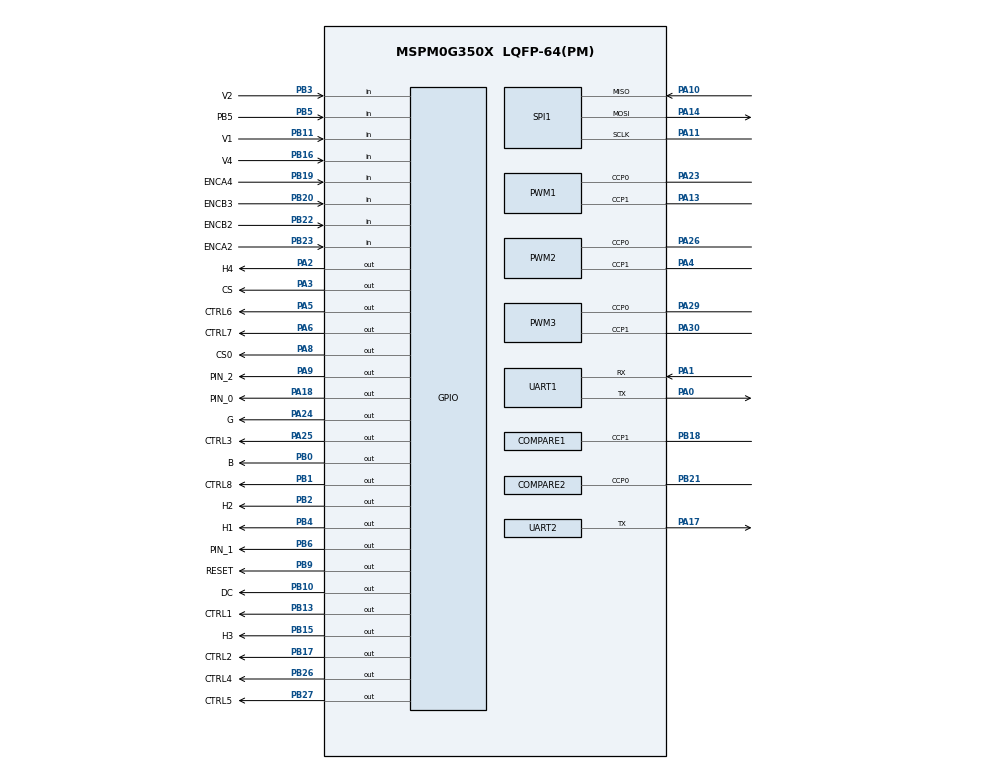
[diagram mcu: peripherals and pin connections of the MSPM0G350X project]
/**
 * @cliArgs --device "MSPM0G350X" --part "Default" --package "LQFP-64(PM)" --product "mspm0_sdk@2.05.01.01"
 * @versions {"tool":"1.23.0+4000"}
 */

/**
 * Import the modules used in this configuration.
 */
const ADC12         = scripting.addModule("/ti/driverlib/ADC12", {}, false);
const ADC121        = ADC12.addInstance();
const ADC122        = ADC12.addInstance();
const COMPARE       = scripting.addModule("/ti/driverlib/COMPARE", {}, false);
const COMPARE1      = COMPARE.addInstance();
const COMPARE2      = COMPARE.addInstance();
const GPIO          = scripting.addModule("/ti/driverlib/GPIO", {}, false);
const GPIO1         = GPIO.addInstance();
const GPIO2         = GPIO.addInstance();
const GPIO3         = GPIO.addInstance();
const GPIO4         = GPIO.addInstance();
const GPIO5         = GPIO.addInstance();
const GPIO6         = GPIO.addInstance();
const GPIO7         = GPIO.addInstance();
const GPIO8         = GPIO.addInstance();
const GPIO9         = GPIO.addInstance();
const GPIO10        = GPIO.addInstance();
const I2C           = scripting.addModule("/ti/driverlib/I2C", {}, false);
const I2C1          = I2C.addInstance();
const NONMAIN       = scripting.addModule("/ti/driverlib/NONMAIN");
const PWM           = scripting.addModule("/ti/driverlib/PWM", {}, false);
const PWM1          = PWM.addInstance();
const PWM2          = PWM.addInstance();
const PWM3          = PWM.addInstance();
const SPI           = scripting.addModule("/ti/driverlib/SPI", {}, false);
const SPI1          = SPI.addInstance();
const SYSCTL        = scripting.addModule("/ti/driverlib/SYSCTL");
const TIMER         = scripting.addModule("/ti/driverlib/TIMER", {}, false);
const TIMER1        = TIMER.addInstance();
const UART          = scripting.addModule("/ti/driverlib/UART", {}, false);
const UART1         = UART.addInstance();
const UART2         = UART.addInstance();
const UART3         = UART.addInstance();
const ProjectConfig = scripting.addModule("/ti/project_config/ProjectConfig");

/**
 * Write custom configuration values to the imported modules.
 */
ADC121.$name                             = "VCC_ADC";
ADC121.sampClkDiv                        = "DL_ADC12_CLOCK_DIVIDE_8";
ADC121.repeatMode                        = true;
ADC121.sampleTime0                       = "100 us";
ADC121.enabledInterrupts                 = ["DL_ADC12_INTERRUPT_MEM0_RESULT_LOADED"];
ADC121.samplingOperationMode             = "sequence";
ADC121.peripheral.adcPin0.$assign        = "PA15";
ADC121.adcPin0Config.hideOutputInversion = scripting.forceWrite(false);
ADC121.adcPin0Config.$name               = "ti_driverlib_gpio_GPIOPinGeneric9";

ADC122.$name                             = "ADC1";
ADC122.sampClkDiv                        = "DL_ADC12_CLOCK_DIVIDE_8";
ADC122.sampleTime0                       = "1ms";
ADC122.adcMem0_name                      = "ADC_Channel0";
ADC122.peripheral.$assign                = "ADC0";
ADC122.peripheral.adcPin0.$assign        = "PA27";
ADC122.adcPin0Config.hideOutputInversion = scripting.forceWrite(false);
ADC122.adcPin0Config.$name               = "ti_driverlib_gpio_GPIOPinGeneric16";

const Board = scripting.addModule("/ti/driverlib/Board", {}, false);

COMPARE1.ccIndex                            = 1;
COMPARE1.timerClkPrescale                   = 2;
COMPARE1.timerPeriod                        = 1;
COMPARE1.interrupts                         = ["LOAD"];
COMPARE1.$name                              = "TIMER_M4";
COMPARE1.peripheral.ccp1Pin.$assign         = "PB18";
COMPARE1.ccp1PinConfig.hideOutputInversion  = scripting.forceWrite(false);
COMPARE1.ccp1PinConfig.onlyInternalResistor = scripting.forceWrite(false);
COMPARE1.ccp1PinConfig.passedPeripheralType = scripting.forceWrite("Digital");
COMPARE1.ccp1PinConfig.$name                = "ti_driverlib_gpio_GPIOPinGeneric7";

COMPARE2.$name                              = "TIMER_M3";
COMPARE2.timerClkPrescale                   = 2;
COMPARE2.timerPeriod                        = 1;
COMPARE2.interrupts                         = ["LOAD"];
COMPARE2.peripheral.ccp0Pin.$assign         = "PB21";
COMPARE2.ccp0PinConfig.hideOutputInversion  = scripting.forceWrite(false);
COMPARE2.ccp0PinConfig.onlyInternalResistor = scripting.forceWrite(false);
COMPARE2.ccp0PinConfig.passedPeripheralType = scripting.forceWrite("Digital");
COMPARE2.ccp0PinConfig.$name                = "ti_driverlib_gpio_GPIOPinGeneric14";

GPIO1.port                                = "PORTB";
GPIO1.$name                               = "KEY1";
GPIO1.associatedPins[0].$name             = "PB5";
GPIO1.associatedPins[0].direction         = "INPUT";
GPIO1.associatedPins[0].interruptEn       = true;
GPIO1.associatedPins[0].polarity          = "FALL";
GPIO1.associatedPins[0].interruptPriority = "1";
GPIO1.associatedPins[0].pin.$assign       = "PB5";

GPIO2.$name                         = "OLED";
GPIO2.associatedPins.create(3);
GPIO2.associatedPins[0].$name       = "RESET";
GPIO2.associatedPins[0].pin.$assign = "PB9";
GPIO2.associatedPins[1].$name       = "DC";
GPIO2.associatedPins[1].pin.$assign = "PB10";
GPIO2.associatedPins[2].$name       = "CS";
GPIO2.associatedPins[2].pin.$assign = "PA3";

GPIO3.$name                         = "MOTOR1";
GPIO3.associatedPins.create(4);
GPIO3.associatedPins[0].$name       = "CTRL1";
GPIO3.associatedPins[0].pin.$assign = "PB13";
GPIO3.associatedPins[1].$name       = "CTRL2";
GPIO3.associatedPins[1].pin.$assign = "PB17";
GPIO3.associatedPins[2].direction   = "INPUT";
GPIO3.associatedPins[2].interruptEn = true;
GPIO3.associatedPins[2].polarity    = "FALL";
GPIO3.associatedPins[2].$name       = "ENCA1";
GPIO3.associatedPins[3].direction   = "INPUT";
GPIO3.associatedPins[3].polarity    = "FALL";
GPIO3.associatedPins[3].$name       = "ENCB1";

GPIO4.$name                         = "MOTOR2";
GPIO4.associatedPins.create(4);
GPIO4.associatedPins[0].$name       = "CTRL3";
GPIO4.associatedPins[0].pin.$assign = "PA25";
GPIO4.associatedPins[1].$name       = "CTRL4";
GPIO4.associatedPins[1].pin.$assign = "PB26";
GPIO4.associatedPins[2].$name       = "ENCA2";
GPIO4.associatedPins[2].direction   = "INPUT";
GPIO4.associatedPins[2].interruptEn = true;
GPIO4.associatedPins[2].polarity    = "FALL";
GPIO4.associatedPins[2].pin.$assign = "PB23";
GPIO4.associatedPins[3].$name       = "ENCB2";
GPIO4.associatedPins[3].direction   = "INPUT";
GPIO4.associatedPins[3].pin.$assign = "PB22";

GPIO5.$name                         = "MOTOR3";
GPIO5.associatedPins.create(3);
GPIO5.associatedPins[0].$name       = "CTRL5";
GPIO5.associatedPins[0].pin.$assign = "PB27";
GPIO5.associatedPins[1].$name       = "CTRL6";
GPIO5.associatedPins[1].pin.$assign = "PA5";
GPIO5.associatedPins[2].$name       = "ENCB3";
GPIO5.associatedPins[2].direction   = "INPUT";
GPIO5.associatedPins[2].interruptEn = true;
GPIO5.associatedPins[2].polarity    = "RISE_FALL";
GPIO5.associatedPins[2].pin.$assign = "PB20";

GPIO6.$name                         = "MOTOR4";
GPIO6.associatedPins.create(3);
GPIO6.associatedPins[0].$name       = "CTRL7";
GPIO6.associatedPins[0].pin.$assign = "PA6";
GPIO6.associatedPins[1].$name       = "CTRL8";
GPIO6.associatedPins[1].pin.$assign = "PB1";
GPIO6.associatedPins[2].$name       = "ENCA4";
GPIO6.associatedPins[2].direction   = "INPUT";
GPIO6.associatedPins[2].interruptEn = true;
GPIO6.associatedPins[2].polarity    = "RISE_FALL";
GPIO6.associatedPins[2].pin.$assign = "PB19";

GPIO7.$name                              = "SPI0";
GPIO7.associatedPins[0].$name            = "CS0";
GPIO7.associatedPins[0].internalResistor = "PULL_UP";
GPIO7.associatedPins[0].pin.$assign      = "PA8";

GPIO8.$name                         = "RGB_GB";
GPIO8.associatedPins.create(2);
GPIO8.associatedPins[0].$name       = "G";
GPIO8.associatedPins[0].pin.$assign = "PA24";
GPIO8.associatedPins[1].$name       = "B";
GPIO8.associatedPins[1].pin.$assign = "PB0";

GPIO9.$name                              = "KEY";
GPIO9.associatedPins.create(8);
GPIO9.associatedPins[0].$name            = "H1";
GPIO9.associatedPins[0].pin.$assign      = "PB4";
GPIO9.associatedPins[1].$name            = "H2";
GPIO9.associatedPins[1].pin.$assign      = "PB2";
GPIO9.associatedPins[2].$name            = "H3";
GPIO9.associatedPins[2].pin.$assign      = "PB15";
GPIO9.associatedPins[3].$name            = "H4";
GPIO9.associatedPins[3].pin.$assign      = "PA2";
GPIO9.associatedPins[4].$name            = "V1";
GPIO9.associatedPins[4].direction        = "INPUT";
GPIO9.associatedPins[4].internalResistor = "PULL_DOWN";
GPIO9.associatedPins[4].pin.$assign      = "PB11";
GPIO9.associatedPins[5].$name            = "V2";
GPIO9.associatedPins[5].direction        = "INPUT";
GPIO9.associatedPins[5].internalResistor = "PULL_DOWN";
GPIO9.associatedPins[5].pin.$assign      = "PB3";
GPIO9.associatedPins[6].direction        = "INPUT";
GPIO9.associatedPins[6].internalResistor = "PULL_DOWN";
GPIO9.associatedPins[6].$name            = "V3";
GPIO9.associatedPins[7].$name            = "V4";
GPIO9.associatedPins[7].direction        = "INPUT";
GPIO9.associatedPins[7].internalResistor = "PULL_DOWN";
GPIO9.associatedPins[7].pin.$assign      = "PB16";

GPIO10.$name                         = "Gray_Address";
GPIO10.associatedPins.create(3);
GPIO10.associatedPins[0].$name       = "PIN_0";
GPIO10.associatedPins[0].pin.$assign = "PA18";
GPIO10.associatedPins[1].$name       = "PIN_1";
GPIO10.associatedPins[1].pin.$assign = "PB6";
GPIO10.associatedPins[2].$name       = "PIN_2";
GPIO10.associatedPins[2].pin.$assign = "PA9";

I2C1.$name                   = "I2C_0";
I2C1.basicEnableController   = true;
I2C1.advControllerRXFIFOTRIG = "BYTES_8";
I2C1.advControllerTXFIFOTRIG = "BYTES_7";
I2C1.sdaPinConfig.$name      = "ti_driverlib_gpio_GPIOPinGeneric8";
I2C1.sclPinConfig.$name      = "ti_driverlib_gpio_GPIOPinGeneric15";

NONMAIN.nonmainWarning    = true;
NONMAIN.bslInvokePinCheck = false;

PWM1.$name                              = "PWM_G0";
PWM1.clockPrescale                      = 10;
PWM1.clockDivider                       = 8;
PWM1.timerStartTimer                    = true;
PWM1.peripheral.$assign                 = "TIMG0";
PWM1.peripheral.ccp0Pin.$assign         = "PA23";
PWM1.peripheral.ccp1Pin.$assign         = "PA13";
PWM1.PWM_CHANNEL_0.$name                = "ti_driverlib_pwm_PWMTimerCC0";
PWM1.PWM_CHANNEL_1.$name                = "ti_driverlib_pwm_PWMTimerCC1";
PWM1.ccp0PinConfig.direction            = scripting.forceWrite("OUTPUT");
PWM1.ccp0PinConfig.hideOutputInversion  = scripting.forceWrite(false);
PWM1.ccp0PinConfig.onlyInternalResistor = scripting.forceWrite(false);
PWM1.ccp0PinConfig.passedPeripheralType = scripting.forceWrite("Digital");
PWM1.ccp0PinConfig.$name                = "ti_driverlib_gpio_GPIOPinGeneric5";
PWM1.ccp1PinConfig.direction            = scripting.forceWrite("OUTPUT");
PWM1.ccp1PinConfig.hideOutputInversion  = scripting.forceWrite(false);
PWM1.ccp1PinConfig.onlyInternalResistor = scripting.forceWrite(false);
PWM1.ccp1PinConfig.passedPeripheralType = scripting.forceWrite("Digital");
PWM1.ccp1PinConfig.$name                = "ti_driverlib_gpio_GPIOPinGeneric6";

PWM2.timerStartTimer                    = true;
PWM2.$name                              = "PWM_MOTOR_1_2";
PWM2.peripheral.$assign                 = "TIMG7";
PWM2.peripheral.ccp0Pin.$assign         = "PA26";
PWM2.peripheral.ccp1Pin.$assign         = "PA4";
PWM2.PWM_CHANNEL_0.$name                = "ti_driverlib_pwm_PWMTimerCC4";
PWM2.PWM_CHANNEL_1.$name                = "ti_driverlib_pwm_PWMTimerCC5";
PWM2.ccp0PinConfig.direction            = scripting.forceWrite("OUTPUT");
PWM2.ccp0PinConfig.hideOutputInversion  = scripting.forceWrite(false);
PWM2.ccp0PinConfig.onlyInternalResistor = scripting.forceWrite(false);
PWM2.ccp0PinConfig.passedPeripheralType = scripting.forceWrite("Digital");
PWM2.ccp0PinConfig.$name                = "ti_driverlib_gpio_GPIOPinGeneric10";
PWM2.ccp1PinConfig.direction            = scripting.forceWrite("OUTPUT");
PWM2.ccp1PinConfig.hideOutputInversion  = scripting.forceWrite(false);
PWM2.ccp1PinConfig.onlyInternalResistor = scripting.forceWrite(false);
PWM2.ccp1PinConfig.passedPeripheralType = scripting.forceWrite("Digital");
PWM2.ccp1PinConfig.$name                = "ti_driverlib_gpio_GPIOPinGeneric11";

PWM3.$name                              = "PWM_MOTOR_3_4";
PWM3.timerStartTimer                    = true;
PWM3.peripheral.$assign                 = "TIMG6";
PWM3.peripheral.ccp0Pin.$assign         = "PA29";
PWM3.peripheral.ccp1Pin.$assign         = "PA30";
PWM3.PWM_CHANNEL_0.$name                = "ti_driverlib_pwm_PWMTimerCC6";
PWM3.PWM_CHANNEL_1.$name                = "ti_driverlib_pwm_PWMTimerCC7";
PWM3.ccp0PinConfig.direction            = scripting.forceWrite("OUTPUT");
PWM3.ccp0PinConfig.hideOutputInversion  = scripting.forceWrite(false);
PWM3.ccp0PinConfig.onlyInternalResistor = scripting.forceWrite(false);
PWM3.ccp0PinConfig.passedPeripheralType = scripting.forceWrite("Digital");
PWM3.ccp0PinConfig.$name                = "ti_driverlib_gpio_GPIOPinGeneric12";
PWM3.ccp1PinConfig.direction            = scripting.forceWrite("OUTPUT");
PWM3.ccp1PinConfig.hideOutputInversion  = scripting.forceWrite(false);
PWM3.ccp1PinConfig.onlyInternalResistor = scripting.forceWrite(false);
PWM3.ccp1PinConfig.passedPeripheralType = scripting.forceWrite("Digital");
PWM3.ccp1PinConfig.$name                = "ti_driverlib_gpio_GPIOPinGeneric13";

SPI1.$name                      = "SPI_0";
SPI1.phase                      = "1";
SPI1.targetBitRate              = 16000000;
SPI1.chipSelect                 = ["0","1"];
SPI1.polarity                   = "1";
SPI1.frameFormat                = "MOTO3";
SPI1.sclkPinConfig.$name        = "ti_driverlib_gpio_GPIOPinGeneric2";
SPI1.mosiPinConfig.$name        = "ti_driverlib_gpio_GPIOPinGeneric3";
SPI1.misoPinConfig.$name        = "ti_driverlib_gpio_GPIOPinGeneric4";
SPI1.peripheral.$assign         = "SPI0";
SPI1.peripheral.sclkPin.$assign = "PA11";
SPI1.peripheral.mosiPin.$assign = "PA14";
SPI1.peripheral.misoPin.$assign = "PA10";


TIMER1.timerMode          = "PERIODIC";
TIMER1.interrupts         = ["ZERO"];
TIMER1.timerClkPrescale   = 20;
TIMER1.$name              = "TIMER_A0_100us";
TIMER1.timerStartTimer    = true;
TIMER1.timerPeriod        = "100 us";
TIMER1.peripheral.$assign = "TIMA0";

UART1.$name                            = "USB_UART_0";
UART1.enabledInterrupts                = ["RX"];
UART1.targetBaudRate                   = 115200;
UART1.interruptPriority                = "0";
UART1.peripheral.rxPin.$assign         = "PA1";
UART1.peripheral.txPin.$assign         = "PA0";
UART1.txPinConfig.direction            = scripting.forceWrite("OUTPUT");
UART1.txPinConfig.hideOutputInversion  = scripting.forceWrite(false);
UART1.txPinConfig.onlyInternalResistor = scripting.forceWrite(false);
UART1.txPinConfig.passedPeripheralType = scripting.forceWrite("Digital");
UART1.txPinConfig.$name                = "ti_driverlib_gpio_GPIOPinGeneric0";
UART1.rxPinConfig.hideOutputInversion  = scripting.forceWrite(false);
UART1.rxPinConfig.onlyInternalResistor = scripting.forceWrite(false);
UART1.rxPinConfig.passedPeripheralType = scripting.forceWrite("Digital");
UART1.rxPinConfig.$name                = "ti_driverlib_gpio_GPIOPinGeneric1";

UART2.$name                    = "UART_1";
UART2.targetBaudRate           = 115200;
UART2.direction                = "TX";
UART2.txPinConfig.$name        = "ti_driverlib_gpio_GPIOPinGeneric18";
UART2.peripheral.$assign       = "UART1";
UART2.peripheral.txPin.$assign = "PA17";

UART3.$name                            = "UART_0";
UART3.txPinConfig.direction            = scripting.forceWrite("OUTPUT");
UART3.txPinConfig.hideOutputInversion  = scripting.forceWrite(false);
UART3.txPinConfig.onlyInternalResistor = scripting.forceWrite(false);
UART3.txPinConfig.passedPeripheralType = scripting.forceWrite("Digital");
UART3.txPinConfig.$name                = "ti_driverlib_gpio_GPIOPinGeneric19";
UART3.rxPinConfig.hideOutputInversion  = scripting.forceWrite(false);
UART3.rxPinConfig.onlyInternalResistor = scripting.forceWrite(false);
UART3.rxPinConfig.passedPeripheralType = scripting.forceWrite("Digital");
UART3.rxPinConfig.$name                = "ti_driverlib_gpio_GPIOPinGeneric20";

ProjectConfig.deviceSpin    = "MSPM0G3507";
ProjectConfig.genLibDrivers = true;

/**
 * Pinmux solution for unlocked pins/peripherals. This ensures that minor changes to the automatic solver in a future
 * version of the tool will not impact the pinmux you originally saw.  These lines can be completely deleted in order to
 * re-solve from scratch.
 */
ADC121.peripheral.$suggestSolution           = "ADC1";
Board.peripheral.$suggestSolution            = "DEBUGSS";
Board.peripheral.swclkPin.$suggestSolution   = "PA20";
Board.peripheral.swdioPin.$suggestSolution   = "PA19";
COMPARE1.peripheral.$suggestSolution         = "TIMA1";
COMPARE2.peripheral.$suggestSolution         = "TIMG8";
GPIO3.associatedPins[2].pin.$suggestSolution = "PB14";
GPIO3.associatedPins[3].pin.$suggestSolution = "PA12";
GPIO9.associatedPins[6].pin.$suggestSolution = "PA16";
I2C1.peripheral.$suggestSolution             = "I2C0";
I2C1.peripheral.sdaPin.$suggestSolution      = "PA28";
I2C1.peripheral.sclPin.$suggestSolution      = "PA31";
SYSCTL.peripheral.$suggestSolution           = "SYSCTL";
UART1.peripheral.$suggestSolution            = "UART0";
UART3.peripheral.$suggestSolution            = "UART2";
UART3.peripheral.rxPin.$suggestSolution      = "PA22";
UART3.peripheral.txPin.$suggestSolution      = "PA21";
